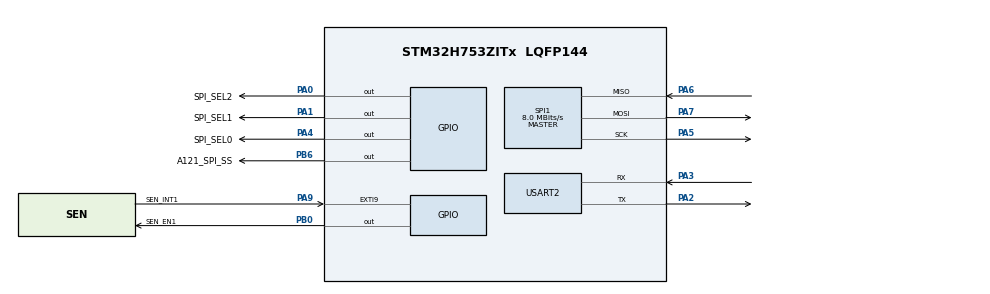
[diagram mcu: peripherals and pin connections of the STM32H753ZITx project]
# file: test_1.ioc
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CORTEX_M7.default_mode_Activation=1
Mcu.Family=STM32H7
Mcu.Name=STM32H753ZITx
Mcu.Package=LQFP144
NVIC.EXTI9_5_IRQn=true\:0\:0\:false\:false\:true\:true\:true\:true
NVIC.PriorityGroup=NVIC_PRIORITYGROUP_4
NVIC.USART2_IRQn=true\:0\:0\:false\:false\:true\:true\:true\:true
PA0.GPIO_Label=SPI_SEL2
PA0.GPIO_Speed=GPIO_SPEED_FREQ_VERY_HIGH
PA0.Signal=GPIO_Output
PA1.GPIO_Label=SPI_SEL1
PA1.GPIO_Speed=GPIO_SPEED_FREQ_VERY_HIGH
PA1.Signal=GPIO_Output
PA2.Mode=Asynchronous
PA2.Signal=USART2_TX
PA3.Mode=Asynchronous
PA3.Signal=USART2_RX
PA4.GPIO_Label=SPI_SEL0
PA4.GPIO_Speed=GPIO_SPEED_FREQ_VERY_HIGH
PA4.Signal=GPIO_Output
PA5.Mode=Full_Duplex_Master
PA5.Signal=SPI1_SCK
PA6.Mode=Full_Duplex_Master
PA6.Signal=SPI1_MISO
PA7.Mode=Full_Duplex_Master
PA7.Signal=SPI1_MOSI
PA9.GPIO_Label=SEN_INT1
PA9.Signal=GPXTI9
PB0.GPIO_Label=SEN_EN1
PB0.GPIO_Speed=GPIO_SPEED_FREQ_VERY_HIGH
PB0.Signal=GPIO_Output
PB6.GPIO_Label=A121_SPI_SS
PB6.GPIO_Speed=GPIO_SPEED_FREQ_VERY_HIGH
PB6.PinState=GPIO_PIN_SET
PB6.Signal=GPIO_Output
ProjectManager.HeapSize=0x200
ProjectManager.StackSize=0x400
ProjectManager.TargetToolchain=STM32CubeIDE
RCC.ADCFreq_Value=32250000
RCC.APB1Freq_Value=16000000
RCC.APB2Freq_Value=16000000
RCC.APB3Freq_Value=16000000
RCC.APB4Freq_Value=16000000
RCC.CortexFreq_Value=16000000
RCC.DIVM1=1
RCC.DIVN1=16
RCC.DIVQ1=8
RCC.HCLKFreq_Value=16000000
RCC.HSIDiv=RCC_PLLSAIDIVR_4
RCC.PLL2FRACN=0
RCC.PLL3FRACN=0
RCC.PLLFRACN=0
RCC.SYSCLKFreq_VALUE=16000000
RCC.USART234578CLockSelection=RCC_USART234578CLKSOURCE_HSI
RCC.USBFreq_Value=32000000
SPI1.BaudRatePrescaler=SPI_BAUDRATEPRESCALER_4
SPI1.CalculateBaudRate=8.0 MBits/s
SPI1.DataSize=SPI_DATASIZE_8BIT
SPI1.Direction=SPI_DIRECTION_2LINES
SPI1.Mode=SPI_MODE_MASTER
SPI1.VirtualType=VM_MASTER
USART2.VirtualMode-Asynchronous=VM_ASYNC
board=custom

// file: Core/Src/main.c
/* USER CODE BEGIN Header */
/**
  ******************************************************************************
  * @file           : main.c
  * @brief          : Main program body
  ******************************************************************************
  * @attention
  *
  * Copyright (c) 2024 STMicroelectronics.
  * All rights reserved.
  *
  * This software is licensed under terms that can be found in the LICENSE file
  * in the root directory of this software component.
  * If no LICENSE file comes with this software, it is provided AS-IS.
  *
  ******************************************************************************
  */
/* USER CODE END Header */
#include "main.h"
#include "spi.h"
#include "usart.h"
#include "gpio.h"

/* USER CODE BEGIN Includes */
#include "acc_hal_definitions_a121.h"
#include "acc_rss_a121.h"
/* USER CODE END Includes */

void SystemClock_Config(void);
static void MPU_Config(void);

int main(void)
{

  /* MPU Configuration--------------------------------------------------------*/
  MPU_Config();

  /* MCU Configuration--------------------------------------------------------*/

  /* Reset of all peripherals, Initializes the Flash interface and the Systick. */
  HAL_Init();

  /* USER CODE BEGIN Init */

      const acc_hal_a121_t *hal = acc_hal_rss_integration_get_implementation();
      if (!acc_rss_hal_register(hal)) {
          // Handle error
      }

  /* USER CODE END Init */

  /* Configure the system clock */
  SystemClock_Config();

  /* Initialize all configured peripherals */
  MX_GPIO_Init();
  MX_SPI1_Init();
  MX_USART2_UART_Init();

  /* Infinite loop */
  while (1)
  {

  }
}

void SystemClock_Config(void)
{
  RCC_OscInitTypeDef RCC_OscInitStruct = {0};
  RCC_ClkInitTypeDef RCC_ClkInitStruct = {0};

  /** Supply configuration update enable
  */
  HAL_PWREx_ConfigSupply(PWR_LDO_SUPPLY);

  /** Configure the main internal regulator output voltage
  */
  __HAL_PWR_VOLTAGESCALING_CONFIG(PWR_REGULATOR_VOLTAGE_SCALE3);

  while(!__HAL_PWR_GET_FLAG(PWR_FLAG_VOSRDY)) {}

  /** Initializes the RCC Oscillators according to the specified parameters
  * in the RCC_OscInitTypeDef structure.
  */
  RCC_OscInitStruct.OscillatorType = RCC_OSCILLATORTYPE_HSI;
  RCC_OscInitStruct.HSIState = RCC_HSI_DIV4;
  RCC_OscInitStruct.HSICalibrationValue = RCC_HSICALIBRATION_DEFAULT;
  RCC_OscInitStruct.PLL.PLLState = RCC_PLL_ON;
  RCC_OscInitStruct.PLL.PLLSource = RCC_PLLSOURCE_HSI;
  RCC_OscInitStruct.PLL.PLLM = 1;
  RCC_OscInitStruct.PLL.PLLN = 16;
  RCC_OscInitStruct.PLL.PLLP = 2;
  RCC_OscInitStruct.PLL.PLLQ = 8;
  RCC_OscInitStruct.PLL.PLLR = 2;
  RCC_OscInitStruct.PLL.PLLRGE = RCC_PLL1VCIRANGE_3;
  RCC_OscInitStruct.PLL.PLLVCOSEL = RCC_PLL1VCOWIDE;
  RCC_OscInitStruct.PLL.PLLFRACN = 0;
  if (HAL_RCC_OscConfig(&RCC_OscInitStruct) != HAL_OK)
  {
    Error_Handler();
  }

  /** Initializes the CPU, AHB and APB buses clocks
  */
  RCC_ClkInitStruct.ClockType = RCC_CLOCKTYPE_HCLK|RCC_CLOCKTYPE_SYSCLK
                              |RCC_CLOCKTYPE_PCLK1|RCC_CLOCKTYPE_PCLK2
                              |RCC_CLOCKTYPE_D3PCLK1|RCC_CLOCKTYPE_D1PCLK1;
  RCC_ClkInitStruct.SYSCLKSource = RCC_SYSCLKSOURCE_HSI;
  RCC_ClkInitStruct.SYSCLKDivider = RCC_SYSCLK_DIV1;
  RCC_ClkInitStruct.AHBCLKDivider = RCC_HCLK_DIV1;
  RCC_ClkInitStruct.APB3CLKDivider = RCC_APB3_DIV1;
  RCC_ClkInitStruct.APB1CLKDivider = RCC_APB1_DIV1;
  RCC_ClkInitStruct.APB2CLKDivider = RCC_APB2_DIV1;
  RCC_ClkInitStruct.APB4CLKDivider = RCC_APB4_DIV1;

  if (HAL_RCC_ClockConfig(&RCC_ClkInitStruct, FLASH_LATENCY_0) != HAL_OK)
  {
    Error_Handler();
  }
}

 /* MPU Configuration */

void MPU_Config(void)
{
  MPU_Region_InitTypeDef MPU_InitStruct = {0};

  /* Disables the MPU */
  HAL_MPU_Disable();

  /** Initializes and configures the Region and the memory to be protected
  */
  MPU_InitStruct.Enable = MPU_REGION_ENABLE;
  MPU_InitStruct.Number = MPU_REGION_NUMBER0;
  MPU_InitStruct.BaseAddress = 0x0;
  MPU_InitStruct.Size = MPU_REGION_SIZE_4GB;
  MPU_InitStruct.SubRegionDisable = 0x87;
  MPU_InitStruct.TypeExtField = MPU_TEX_LEVEL0;
  MPU_InitStruct.AccessPermission = MPU_REGION_NO_ACCESS;
  MPU_InitStruct.DisableExec = MPU_INSTRUCTION_ACCESS_DISABLE;
  MPU_InitStruct.IsShareable = MPU_ACCESS_SHAREABLE;
  MPU_InitStruct.IsCacheable = MPU_ACCESS_NOT_CACHEABLE;
  MPU_InitStruct.IsBufferable = MPU_ACCESS_NOT_BUFFERABLE;

  HAL_MPU_ConfigRegion(&MPU_InitStruct);
  /* Enables the MPU */
  HAL_MPU_Enable(MPU_PRIVILEGED_DEFAULT);

}

void Error_Handler(void)
{
  __disable_irq();
  while (1)
  {
  }
}
